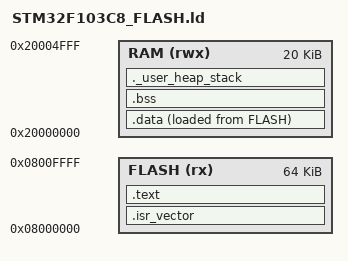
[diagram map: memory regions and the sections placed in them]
/* STM32F103C8Tx: 64 KB flash, 20 KB SRAM */
MEMORY
{
  FLASH (rx)  : ORIGIN = 0x08000000, LENGTH = 64K
  RAM   (rwx) : ORIGIN = 0x20000000, LENGTH = 20K
}

_estack = ORIGIN(RAM) + LENGTH(RAM);

SECTIONS
{
  .isr_vector :
  {
    KEEP(*(.isr_vector))
  } > FLASH

  .text :
  {
    *(.text.Reset_Handler)
    *(.text.Default_Handler)
    *(.text*)
    *(.rodata*)
  } > FLASH

  _sidata = LOADADDR(.data);

  .data :
  {
    _sdata = .;
    *(.data*)
    _edata = .;
  } > RAM AT> FLASH

  .bss :
  {
    _sbss = .;
    *(.bss*)
    *(COMMON)
    _ebss = .;
  } > RAM

  ._user_heap_stack (NOLOAD) :
  {
    . = ALIGN(8);
    . = . + 0x400; /* minimum heap/stack reserve, catches overflow at link time */
    . = ALIGN(8);
  } > RAM

  /DISCARD/ :
  {
    *(.ARM.exidx*)
  }
}
